AUTOSAR XML (schema 4-0-3)
package /ComponentTypes
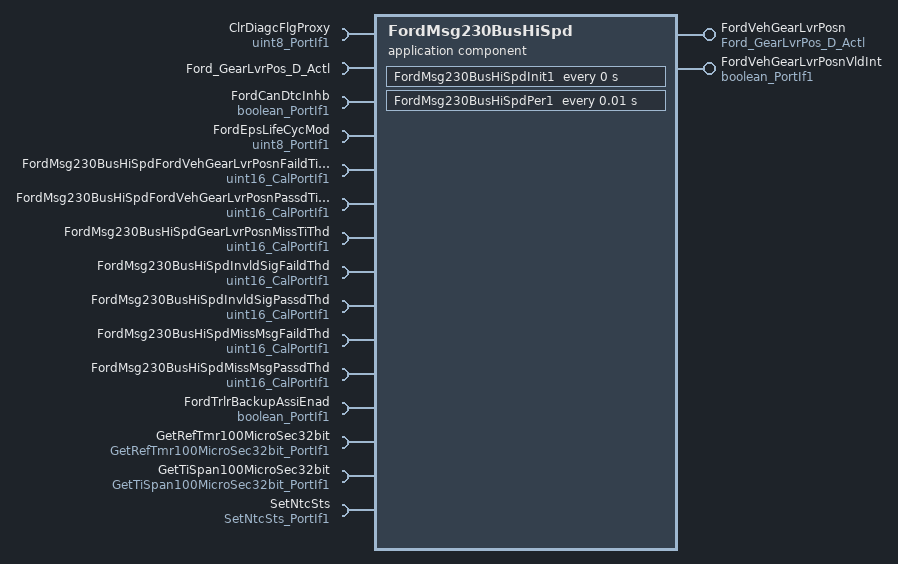
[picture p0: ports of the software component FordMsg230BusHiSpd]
  application sw component type FordMsg230BusHiSpd  # The purpose of the Ford Message 230 Bus High Speed function is to provide the Electric Power Steering systemwith Trailer Back up Assist and Gear Lever Position signals from CAN. The Ford Message 230 function will perform the missing message and signal invalid diagnostics as well as provide a validity signal for the signalvalues and received message.
    provide port FordVehGearLvrPosn: nonqueued-sender-com-spec{data-element=Ford_GearLvrPos_D_Actl, init-value=14}, provided-interface=Ford_GearLvrPos_D_Actl  # Processed value of Gear Lever Position to be used by EPS.
    provide port FordVehGearLvrPosnVldInt: nonqueued-sender-com-spec{data-element=Logl, init-value=0}, provided-interface=boolean_PortIf1  # This output tells if the value for Ford Vehicle Gear Lever Position is valid or not.
    15 x require port:
      ClrDiagcFlgProxy: nonqueued-receiver-com-spec{data-element=Val, filter=data-filter-type=ALWAYS, init-value=0}, required-interface=uint8_PortIf1  # When ClrDiagcFlgProxy is True, Diagnostic test is performed.
      Ford_GearLvrPos_D_Actl: nonqueued-receiver-com-spec{data-element=Ford_GearLvrPos_D_Actl, filter=data-filter-type=ALWAYS, init-value=14}, required-interface=Ford_GearLvrPos_D_Actl  # It is a message signal which is received from CAN bus which will be processed and used in EPS.Customer Data type : Ford_GearLvrPos_D_Actl; Cx0_Park(0), Cx1_Reverse(1), Cx2_Neutral(2), Cx3_Drive(3), Cx4_Sport_DriveSport(4), Cx5_Low(5), Cx6_first(6), Cx7_second(7), Cx8_third(8),Cx9_fourth(9), CxA_fifth(10), CxB_sixth(11), CxC_Undefined_Treat_as_Fault(12), CxD_Undefined_Treat_as_Fault(13), CxE_Unknown_Position(14)CxF_Fault(15).
      FordCanDtcInhb: nonqueued-receiver-com-spec{data-element=Logl, filter=data-filter-type=ALWAYS, init-value=1}, required-interface=boolean_PortIf1  # This signal should be set to 0 in order to Test Diagnostic NTC.Customer datatype should be used. Data Type: Boolean with Min value “False”(0), Init value “True”(1) and Max value “True”(1).
      FordEpsLifeCycMod: nonqueued-receiver-com-spec{data-element=Val, filter=data-filter-type=ALWAYS, init-value=0}, required-interface=uint8_PortIf1  # This signal is used to decide calibration value to FAIL the NTC.
      FordMsg230BusHiSpdFordVehGearLvrPosnFaildTiThd: parameter-require-com-spec{init-value=0, parameter=Val}, required-interface=uint16_CalPortIf1  # Threshold to set the output Ford Vehicle Gear Lever Position Valid to False.
      FordMsg230BusHiSpdFordVehGearLvrPosnPassdTiThd: parameter-require-com-spec{init-value=0, parameter=Val}, required-interface=uint16_CalPortIf1  # Threshold to set the output Ford Vehicle Gear Lever Position Valid to True.
      FordMsg230BusHiSpdGearLvrPosnMissTiThd: parameter-require-com-spec{init-value=5000, parameter=Val}, required-interface=uint16_CalPortIf1  # Threshold to set the output Ford Vehicle Gear Lever Position Valid to False.
      FordMsg230BusHiSpdInvldSigFaildThd: parameter-require-com-spec{init-value=0, parameter=Val}, required-interface=uint16_CalPortIf1  # Threshold to set the Invalid message NTC.
      FordMsg230BusHiSpdInvldSigPassdThd: parameter-require-com-spec{init-value=0, parameter=Val}, required-interface=uint16_CalPortIf1  # Threshold to Reset the Invalid message NTC.
      FordMsg230BusHiSpdMissMsgFaildThd: parameter-require-com-spec{init-value=5000, parameter=Val}, required-interface=uint16_CalPortIf1  # Threshold to set the Missing message NTC.
      FordMsg230BusHiSpdMissMsgPassdThd: parameter-require-com-spec{init-value=0, parameter=Val}, required-interface=uint16_CalPortIf1  # Threshold to reset the Missing message NTC.
      FordTrlrBackupAssiEnad: nonqueued-receiver-com-spec{data-element=Logl, filter=data-filter-type=ALWAYS, init-value=0}, required-interface=boolean_PortIf1  # It is a message signal which is received from CAN bus which will be processed and used in EPS.Customer datatype should be used. Data Type: Boolean with Min value “False”(0),Init value “False”(0) and Max value “True”(1).
      GetRefTmr100MicroSec32bit: client-com-spec=Oper, required-interface=GetRefTmr100MicroSec32bit_PortIf1  # It captures simulation time from the SimnTi value obtained at root layer of model and gives the RefTmr.
      GetTiSpan100MicroSec32bit: client-com-spec=Oper, required-interface=GetTiSpan100MicroSec32bit_PortIf1  # It Captures simulation time fromSimnTi value, handles counter wrapping and subtracts RefTmr, provides the TiSpan.
      SetNtcSts: client-com-spec=Oper, required-interface=SetNtcSts_PortIf1  # Set the NTC status.
    behavior FordMsg230BusHiSpd_InternalBehavior
      ar-typed-per-instance-memorys:
        12 x data, all with sw-calibration-access=READ-ONLY:
          ClrDiagcFlgProxyPrev: type=uint8  # Clear Diagc Flag Proxy Previous.
          FirstTranVldFlg: type=boolean  # This flag is used to indicate the reception of first message.
          FordVehGearLvrPosnInvldFaildRefTi: type=uint32  # Timer for Invalid message will increment or reset based on the condition.
          FordVehGearLvrPosnInvldPassdRefTi: type=uint32  # Timer for Invalid message will increment or reset based on the condition.
          FordVehGearLvrPosnPrev: type=Ford_GearLvrPos_D_Actl  # Previous value of Ford Vehicle Gear Lever Position.
          FordVehGearLvrPosnVldFaildRefTi: type=uint32  # Timer for Gear Lever Position Valid Failed Reference Time will increment or reset based on the conditions.
          FordVehGearLvrPosnVldIntPrev: type=boolean  # Previous value of Ford Vehicle Gear Lever Position Valid Internal.
          FordVehGearLvrPosnVldPassdRefTi: type=uint32  # Timer for Gear Lever Position Valid Failed Reference Time will increment or reset based on the conditions.
          FordVehMsg230Miss: type=boolean  # Used to hold value of Ford Vehicle message 230 miss.
          GearLvrPosnVldMissRefTi: type=uint32  # Timer for Gear Lever Position Valid Missing Reference Time will increment or reset based on the conditions.
          MissMsgFaildRefTi: type=uint32  # Timer for missing message will increment or reset based on the conditions.
          MissMsgPassdRefTi: type=uint32  # Timer for missing message will increment or reset based on the conditions.
      timing event FordMsg230BusHiSpd_InitEvent: start-on-event=FordMsg230BusHiSpdInit1, period=0
      timing event TMT_FordMsg230BusHiSpdPer1: start-on-event=FordMsg230BusHiSpdPer1, period=0.01
      runnable FordMsg230BusHiSpdInit1  # Initialization Runnable
        sync call SC_GetRefTmr100MicroSec32bit_Oper: operation=GetRefTmr100MicroSec32bit.Oper, timeout=0
      runnable FordMsg230BusHiSpdPer1  # Periodic Runnable at 10 milli-seconds
        data-receive-point-by-arguments:
          5 x access:
            REC_ClrDiagcFlgProxy_Val: accessed-variable=ClrDiagcFlgProxy.Val
            REC_Ford_GearLvrPos_D_Actl_Ford_GearLvrPos_D_Actl: accessed-variable=Ford_GearLvrPos_D_Actl.Ford_GearLvrPos_D_Actl
            REC_FordCanDtcInhb_Logl: accessed-variable=FordCanDtcInhb.Logl
            REC_FordEpsLifeCycMod_Val: accessed-variable=FordEpsLifeCycMod.Val
            REC_FordTrlrBackupAssiEnad_Logl: accessed-variable=FordTrlrBackupAssiEnad.Logl
        data-send-points:
          access SEND_FordVehGearLvrPosn_Ford_GearLvrPos_D_Actl: accessed-variable=FordVehGearLvrPosn.Ford_GearLvrPos_D_Actl
          access SEND_FordVehGearLvrPosnVldInt_Logl: accessed-variable=FordVehGearLvrPosnVldInt.Logl
        sync call SC_GetRefTmr100MicroSec32bit_Oper: operation=GetRefTmr100MicroSec32bit.Oper, timeout=0
        sync call SC_GetTiSpan100MicroSec32bit_Oper: operation=GetTiSpan100MicroSec32bit.Oper, timeout=0
        sync call SC_SetNtcSts_Oper: operation=SetNtcSts.Oper, timeout=0
  swc implementation FordMsg230BusHiSpd_Implementation: behavior=FordMsg230BusHiSpd_InternalBehavior
    code-descriptors:
      code Default: artifact-descriptors=autosar-engineering-object={short-label=Default, category=SWSRC}
